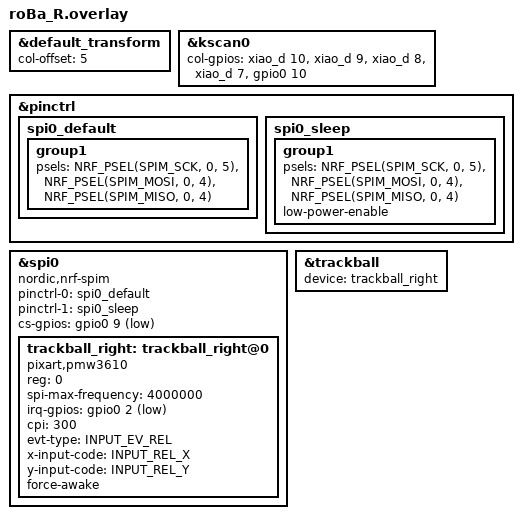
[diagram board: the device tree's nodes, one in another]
#include "roBa.dtsi"

#define INPUT_EV_KEY 0x01               /**< Key event */
#define INPUT_EV_REL 0x02               /**< Relative coordinate event */
#define INPUT_EV_ABS 0x03               /**< Absolute coordinate event */
#define INPUT_EV_MSC 0x04               /**< Miscellaneous event */
#define INPUT_EV_VENDOR_START 0xf0      /**< Vendor specific event start */
#define INPUT_EV_VENDOR_STOP 0xff       /**< Vendor specific event stop */

#define INPUT_REL_X 0x00                /**< Relative X coordinate */
#define INPUT_REL_Y 0x01                /**< Relative Y coordinate */
#define INPUT_REL_WHEEL 0x08            /**< Relative wheel coordinate */
#define INPUT_REL_HWHEEL 0x06           /**< Relative horizontal wheel coordinate */
#define INPUT_REL_MISC 0x09             /**< Relative misc coordinate */

&default_transform {
    col-offset = <5>;
};

&kscan0 {
        col-gpios
            = <&xiao_d 10 GPIO_ACTIVE_HIGH>
            , <&xiao_d 9 GPIO_ACTIVE_HIGH> 
            , <&xiao_d 8 GPIO_ACTIVE_HIGH> 
            , <&xiao_d 7 GPIO_ACTIVE_HIGH> 
            , <&gpio0 10 GPIO_ACTIVE_HIGH>
            ;
};


&pinctrl {
    spi0_default: spi0_default {
        group1 {
            psels = <NRF_PSEL(SPIM_SCK, 0, 5)>,
                <NRF_PSEL(SPIM_MOSI, 0, 4)>,
                <NRF_PSEL(SPIM_MISO, 0, 4)>;
        };
    };

    spi0_sleep: spi0_sleep {
        group1 {
            psels = <NRF_PSEL(SPIM_SCK, 0, 5)>,
                <NRF_PSEL(SPIM_MOSI, 0, 4)>,
                <NRF_PSEL(SPIM_MISO, 0, 4)>;
            low-power-enable;
        };
    };
};

#include <zephyr/dt-bindings/input/input-event-codes.h>

&spi0 {
    status = "okay";
    compatible = "nordic,nrf-spim";
    pinctrl-0 = <&spi0_default>;
    pinctrl-1 = <&spi0_sleep>;
    pinctrl-names = "default", "sleep";
    cs-gpios = <&gpio0 9 GPIO_ACTIVE_LOW>;

    trackball_right: trackball_right@0 {
        status = "okay";
        compatible = "pixart,pmw3610";
        reg = <0>;
        spi-max-frequency = <4000000>;
        irq-gpios = <&gpio0 2 (GPIO_ACTIVE_LOW | GPIO_PULL_UP)>;
        cpi = <300>;
        evt-type = <INPUT_EV_REL>;
        x-input-code = <INPUT_REL_X>;
        y-input-code = <INPUT_REL_Y>;

        force-awake;
        /* keep the sensor awake while ZMK activity state is ACTIVE,
           fallback to normal downshift mode after ZMK goes into IDLE / SLEEP mode.
           thus, the sensor would be a `wakeup-source` */
    };
};

&trackball {
    device = <&trackball_right>;
};
